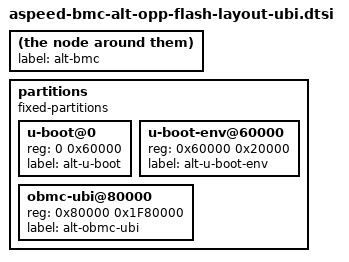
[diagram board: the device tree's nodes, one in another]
		label = "alt-bmc";
		partitions {
				#address-cells = < 1 >;
				#size-cells = < 1 >;
				compatible = "fixed-partitions";
				u-boot@0 {
					reg = < 0 0x60000 >;
					label = "alt-u-boot";
				};
				u-boot-env@60000 {
					reg = < 0x60000 0x20000 >;
					label = "alt-u-boot-env";
				};
				obmc-ubi@80000 {
					reg = < 0x80000 0x1F80000 >;
					label = "alt-obmc-ubi";
				};
		};
